# RZT2M register map
Vendor: Renesas Electronics Corporation; Series: RZT; File version: 1.20.01
CPU: other r0p0, little endian, MPU, no FPU, VTOR, 4 interrupt priority bits, 624 interrupts
Registers are 32-bit, read-write, reset 0x0 unless marked. A register's access mark holds for its fields unless they carry their own. Offsets are from the block's base; [hi:lo] are bit positions; {n}, {i} and the like mark numbered series; 'fields as' and 'values as' point back to an identical list.

## SYSRAM_CTL — System SRAM Control
Base 0x81281800
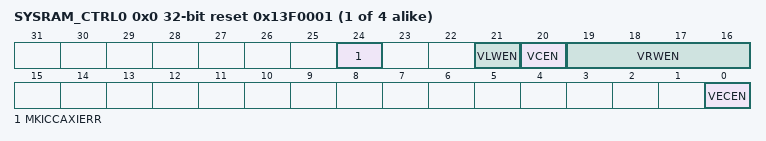
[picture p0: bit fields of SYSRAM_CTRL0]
{0x0+0x10*i} SYSRAM_CTRL{i} (i=0..3) reset 0x13F0001 — System SRAM Control Register {i}
  [24] MKICCAXIERR — Controls AXI-SLVERR issuance for ECC 2-bit errors
    0=Issue AXI-SLEVER; 1=Do not issue AXI-SLEVER
  [21] VLWEN — Enables write for RAM
    0=Disabled; 1=Enabled
  [20] VCEN — Enables access to RAM
    0=Disabled; 1=Enabled
  [19:16] VRWEN — Enables write for each page of RAM
    0=Disabled; 1=Enabled
  [0] VECEN — Enables or disables error correction with ECC
    0=Disabled; 1=Enabled

## TCMAW — TCM access wait state
Base 0x81281900
0x10 CPU0WAIT ro (reset mask 0xFFFFFFFE) — CPU0 ATCM Wait State Register
  [0] CPU0WAIT — ATCM Wait state
    0=0-wait state (MDW = 0); 1=1-wait state (MDW = 1)

## RWP_S — Register Write Protection for Safety Area
Base 0x81281A00
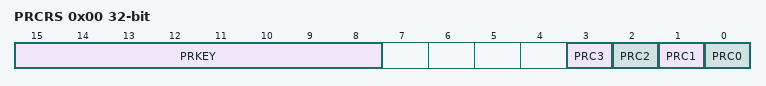
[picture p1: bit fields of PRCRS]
0x00 PRCRS — Safety Area Protect Register
  [15:8] PRKEY wo — PRC Key Code
  [n] PRC{n} (n=0..3) — Protect {n}
    0=Write disabled; 1=Write enabled

## MPU_AC — Master MPU Access Control
Base 0x81282000
0x00 CPU1_CTRL — CPU1 Access Permission Control Register
  [0] CPU1_CTRL — CPU1 access permission control to Master MPU related registers
    0=Access prohibited; 1=Access permitted

## MTU_NF — Multi-Function Timer Pulse Unit Noise Filter
Base 0x90001290
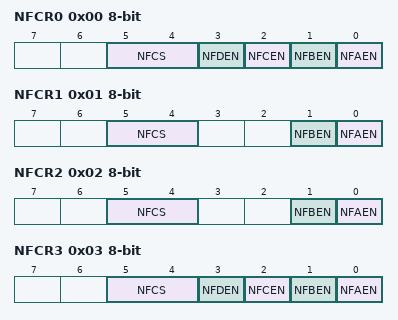
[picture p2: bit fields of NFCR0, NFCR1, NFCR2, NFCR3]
0x00 NFCR0 8-bit — Noise Filter Control Register 0
  [5:4] NFCS — Noise Filter Clock Select
    0=PCLKH/1; 1=PCLKH/8; 2=PCLKH/32; 3=Clock source for counting
  [3] NFDEN — Noise Filter D Enable
    0=The noise filter for the MTIOCnD pin is disabled; 1=The noise filter for the MTIOCnD pin is enabled
  [2] NFCEN — Noise Filter C Enable
    0=The noise filter for the MTIOCnC pin is disabled; 1=The noise filter for the MTIOCnC pin is enabled
  [1] NFBEN — Noise Filter B Enable
    0=The noise filter for the MTIOCnB pin is disabled; 1=The noise filter for the MTIOCnB pin is enabled
  [0] NFAEN — Noise Filter A Enable
    0=The noise filter for the MTIOCnA pin is disabled; 1=The noise filter for the MTIOCnA pin is enabled
0x01 NFCR1 8-bit — Noise Filter Control Register 1
  [5:4] NFCS — Noise Filter Clock Select
    values as NFCR0.NFCS
  [1] NFBEN — Noise Filter B Enable
    0=The noise filter for the MTIOCmB pin is disabled; 1=The noise filter for the MTIOCmB pin is enabled
  [0] NFAEN — Noise Filter A Enable
    0=The noise filter for the MTIOCmA pin is disabled; 1=The noise filter for the MTIOCmA pin is enabled
0x02 NFCR2 8-bit — Noise Filter Control Register 2
  fields as NFCR1
0x03 NFCR3 8-bit — Noise Filter Control Register 3
  fields as NFCR0
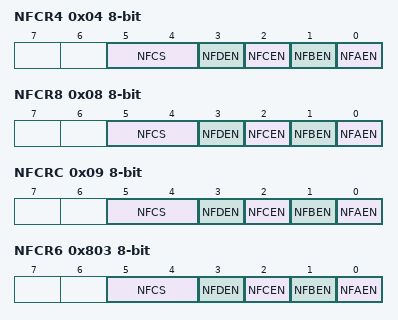
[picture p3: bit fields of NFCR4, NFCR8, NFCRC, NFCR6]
0x04 NFCR4 8-bit — Noise Filter Control Register 4
  fields as NFCR0
0x08 NFCR8 8-bit — Noise Filter Control Register 8
  fields as NFCR0
0x09 NFCRC 8-bit — Noise Filter Control Register C
  [5:4] NFCS — Noise Filter Clock Select
    0=PCLKH/1; 1=PCLKH/2; 2=PCLKH/8; 3=PCLKH/32
  [3] NFDEN — Noise Filter D Enable
    0=The noise filter for the MTCLKD pin is disabled; 1=The noise filter for the MTCLKD pin is enabled
  [2] NFCEN — Noise Filter C Enable
    0=The noise filter for the MTCLKC pin is disabled; 1=The noise filter for the MTCLKC pin is enabled
  [1] NFBEN — Noise Filter B Enable
    0=The noise filter for the MTCLKB pin is disabled; 1=The noise filter for the MTCLKB pin is enabled
  [0] NFAEN — Noise Filter A Enable
    0=The noise filter for the MTCLKA pin is disabled; 1=The noise filter for the MTCLKA pin is enabled
0x803 NFCR6 8-bit — Noise Filter Control Register 6
  fields as NFCR0
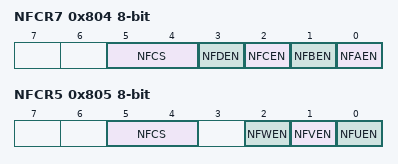
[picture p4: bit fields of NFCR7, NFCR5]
0x804 NFCR7 8-bit — Noise Filter Control Register 7
  fields as NFCR0
0x805 NFCR5 8-bit — Noise Filter Control Register 5
  [5:4] NFCS — Noise Filter Clock Select
    values as NFCR0.NFCS
  [2] NFWEN — Noise Filter W Enable
    0=The noise filter for the MTIC5W pin is disabled; 1=The noise filter for the MTIC5W pin is enabled
  [1] NFVEN — Noise Filter V Enable
    0=The noise filter for the MTIC5V pin is disabled; 1=The noise filter for the MTIC5V pin is enabled
  [0] NFUEN — Noise Filter U Enable
    0=The noise filter for the MTIC5U pin is disabled; 1=The noise filter for the MTIC5U pin is enabled
